# M411_unitA register map
File version: 2.0.2.2
Registers are 32-bit, read-write, reset 0x0 unless marked. A register's access mark holds for its fields unless they carry their own. Offsets are from the block's base; [hi:lo] are bit positions; {n}, {i} and the like mark numbered series.

## PF — Port F (PF)
Base 0x400C0500
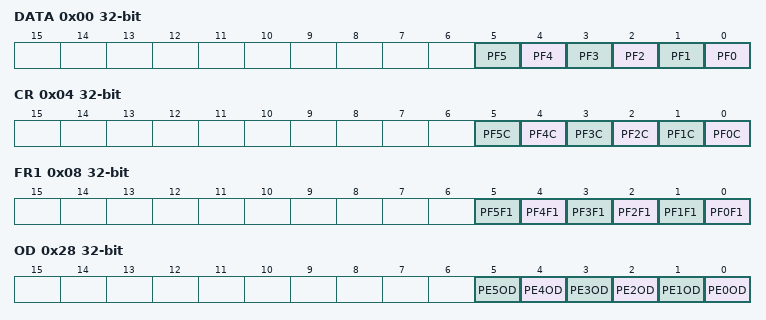
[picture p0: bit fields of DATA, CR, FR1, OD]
0x00 DATA — Port F Data Register
  [n] PF{n} (n=0..5)
0x04 CR — Port F Output Control Register
  [n] PF{n}C (n=0..5)
0x08 FR1 — Port F Function Register 1
  [n] PF{n}F1 (n=0..5)
0x28 OD — Port F Open-drain Control Register
  [n] PE{n}OD (n=0..5)
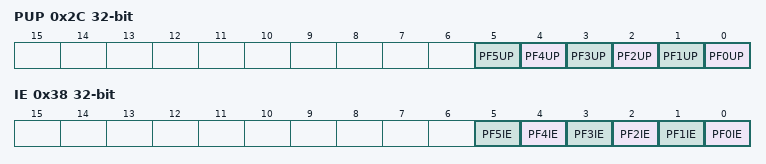
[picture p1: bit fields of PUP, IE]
0x2C PUP — Port F Pull-up Control Register
  [n] PF{n}UP (n=0..5)
0x38 IE — Port F Input Control Register
  [n] PF{n}IE (n=0..5)

## PG — Port G (PG)
Base 0x400C0600
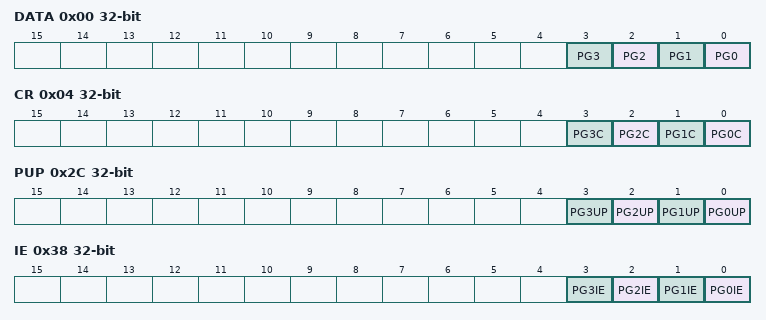
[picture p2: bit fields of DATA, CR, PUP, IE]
0x00 DATA — Port G Data Register
  [n] PG{n} (n=0..3)
0x04 CR — Port G Output Control Register
  [n] PG{n}C (n=0..3)
0x2C PUP — Port G Pull-up Control Register
  [n] PG{n}UP (n=0..3)
0x38 IE — Port G Input Control Register
  [n] PG{n}IE (n=0..3)

## TB0 — 16-bit Timer_Event Counter (TB)
Base 0x400C4000
Same registers: TB1 0x400C4100, TB2 0x400C4200
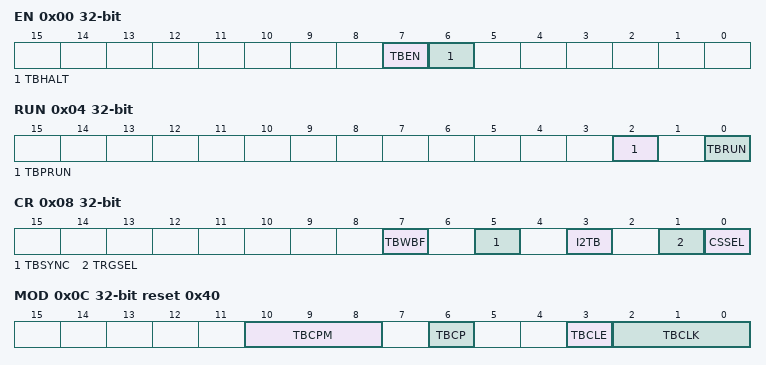
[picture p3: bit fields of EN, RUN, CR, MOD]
0x00 EN — TB Enable Register
  [7] TBEN, [6] TBHALT
0x04 RUN — TB RUN Register
  [2] TBPRUN, [0] TBRUN
0x08 CR — TB Control Register
  [7] TBWBF, [5] TBSYNC, [3] I2TB, [1] TRGSEL, [0] CSSEL
0x0C MOD reset 0x40 — TB Mode Register
  [10:8] TBCPM, [6] TBCP wo, [3] TBCLE, [2:0] TBCLK
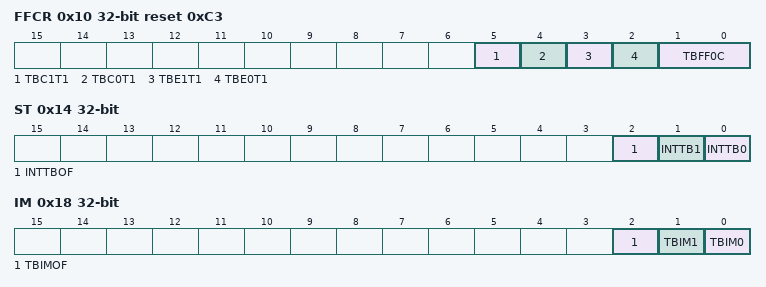
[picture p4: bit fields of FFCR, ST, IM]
0x10 FFCR reset 0xC3 — TB Flip-Flop Control Register
  [5] TBC1T1, [4] TBC0T1, [3] TBE1T1, [2] TBE0T1, [1:0] TBFF0C
0x14 ST ro — TB Status Register
  [2] INTTBOF, [1] INTTB1, [0] INTTB0
0x18 IM — TB Interrupt Mask Register
  [2] TBIMOF, [1] TBIM1, [0] TBIM0
0x1C UC ro — TB Up-counter Capture Register
  [15:0] TBUC
0x20 RG0 — TB RG0 Timer Register
  [15:0] TBRG0
0x24 RG1 — TB RG1 Timer Register
  [15:0] TBRG1
0x28 CP0 ro (reset mask 0xFFFF0000) — TB CP0 Capture Register
  [15:0] TBCP0
0x2C CP1 ro (reset mask 0xFFFF0000) — TB CP1 Capture Register
  [15:0] TBCP1

## RTC — Real Time Clock (RTC)
Base 0x400CC000
0x00 SECR 8-bit (reset mask 0x80) — RTC Second Column Register
  [6:0] SE
0x01 MINR 8-bit (reset mask 0x80) — RTC Minute Column Register
  [6:0] MI
0x02 HOURR 8-bit (reset mask 0xC0) — RTC Hour Column Register
  [5:0] HO
0x04 DAYR 8-bit (reset mask 0xF8) — RTC Day of the Week Column Register
  [2:0] WE
0x05 DATER 8-bit (reset mask 0xC0) — RTC Day Column Register
  [5:0] DA
0x06 MONTHR 8-bit (reset mask 0xE0) — RTC Month Column Register
  [4:0] MO
0x07 YEARR 8-bit reset not defined — RTC Year Column Register
  [7:0] YE
0x08 TPROD 8-bit (reset mask 0xFE) — RTC (AM_PM) Selection Register
  [0] MO0
0x09 LEAPR 8-bit (reset mask 0xFC) — RTC Leap Year Register
  [1:0] LEAP
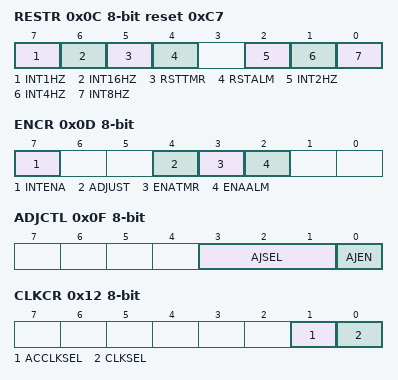
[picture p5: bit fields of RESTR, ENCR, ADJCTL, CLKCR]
0x0C RESTR 8-bit reset 0xC7 — RTC Reset Register
  [7] INT1HZ, [6] INT16HZ, [5] RSTTMR, [4] RSTALM, [2] INT2HZ, [1] INT4HZ, [0] INT8HZ
0x0D ENCR 8-bit (reset mask 0xF7)
  [7] INTENA, [4] ADJUST, [3] ENATMR, [2] ENAALM
0x0E PROTECT 8-bit reset 0xC1 — RTC protect register
  [7:0] RTCPROTECT
0x0F ADJCTL 8-bit (reset mask 0xF0) — Clock Correction Function Control Register
  [3:1] AJSEL, [0] AJEN
0x10 ADJDAT 16-bit (reset mask 0xFE00) — Clock Correction Value Register
  [8:0] ADJDAT
0x12 CLKCR 8-bit — Clock Control Register
  [1] ACCLKSEL, [0] CLKSEL
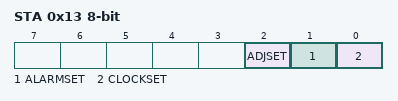
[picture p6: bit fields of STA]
0x13 STA 8-bit — Transfer Enable Register
  [2] ADJSET, [1] ALARMSET, [0] CLOCKSET
0x20 ASECR 8-bit (reset mask 0x80) — Alarm Second Column Register
  [6:0] SE
0x21 AMINR 8-bit (reset mask 0x80) — Alarm Minute Column Register
  [6:0] MI
0x22 AHOURR 8-bit (reset mask 0xC0) — Alarm Hour Column Register
  [5:0] HO
0x24 ADAYR 8-bit (reset mask 0xF8) — Alarm Day of the Week Column Register
  [2:0] WE
0x25 ADATER 8-bit (reset mask 0xC0) — Alarm Day Column Register
  [5:0] DA

## SC0 — SIO_UART (SC)
Base 0x400E1000
Same registers: SC1 0x400E1100
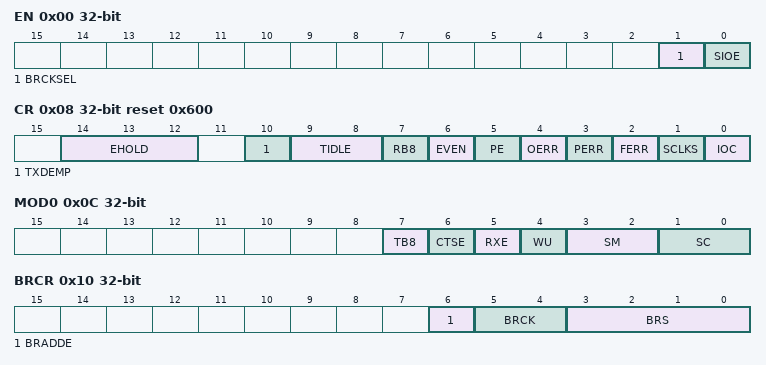
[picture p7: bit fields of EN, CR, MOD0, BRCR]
0x00 EN — SC Enable Register
  [1] BRCKSEL, [0] SIOE
0x04 BUF — SC Buffer Register
  [7:0] TB_RB
0x08 CR reset 0x600 — SC Control Register
  [14:12] EHOLD, [10] TXDEMP, [9:8] TIDLE, [7] RB8 ro, [6] EVEN, [5] PE, [4] OERR ro, [3] PERR ro, [2] FERR ro, [1] SCLKS, [0] IOC
0x0C MOD0 — SC Mode Control Register 0
  [7] TB8, [6] CTSE, [5] RXE, [4] WU, [3:2] SM, [1:0] SC
0x10 BRCR — SC Baud Rate Generator Control Register
  [6] BRADDE, [5:4] BRCK, [3:0] BRS
0x14 BRADD — SC Baud Rate Generator Control Register 2
  [3:0] BRK
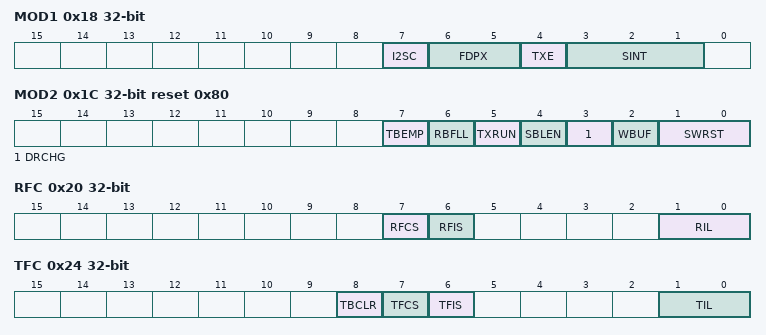
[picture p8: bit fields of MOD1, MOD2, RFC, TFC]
0x18 MOD1 — SC Mode Control Register 1
  [7] I2SC, [6:5] FDPX, [4] TXE, [3:1] SINT
0x1C MOD2 reset 0x80 — SC Mode Control Register 2
  [7] TBEMP ro, [6] RBFLL ro, [5] TXRUN ro, [4] SBLEN, [3] DRCHG, [2] WBUF, [1:0] SWRST
0x20 RFC — SC RX FIFO Configuration Register
  [7] RFCS wo, [6] RFIS, [1:0] RIL
0x24 TFC — SC TX FIFO Configuration Register
  [8] TBCLR wo, [7] TFCS wo, [6] TFIS, [1:0] TIL
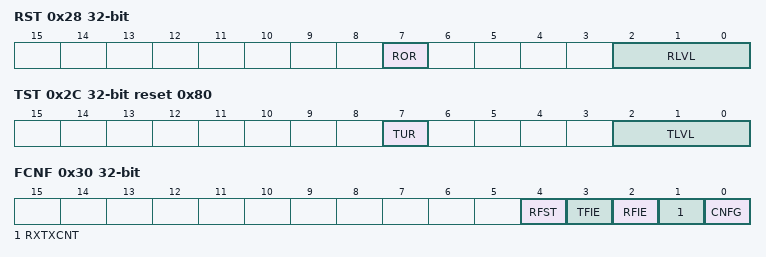
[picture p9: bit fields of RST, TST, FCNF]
0x28 RST ro — SC RX FIFO Status Register
  [7] ROR, [2:0] RLVL
0x2C TST ro reset 0x80 — SC TX FIFO Status Register
  [7] TUR, [2:0] TLVL
0x30 FCNF — SC FIFO Configuration Register
  [4] RFST, [3] TFIE, [2] RFIE, [1] RXTXCNT, [0] CNFG

## WD — Watchdog Timer (WD)
Base 0x400F2000
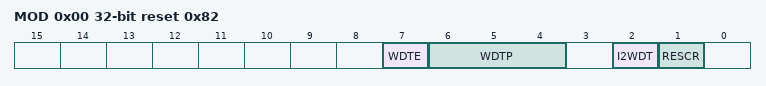
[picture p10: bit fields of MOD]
0x00 MOD reset 0x82 — Mode Register
  [7] WDTE, [6:4] WDTP, [2] I2WDT, [1] RESCR
0x04 CR wo — Control Register
  [7:0] WDCR
0x08 FLG ro — Flag Register
  [0] FLG

## CG — Clock Control (CG)
Base 0x400F3000
0x00 PROTECT reset 0xC1
  [7:0] CGPROTECT
0x04 OSCSEL — High-speed oscillation select Register
  [1:0] OSCSEL
0x08 OSCSTF ro — High-speed oscillation status Register
  [1:0] OSCF
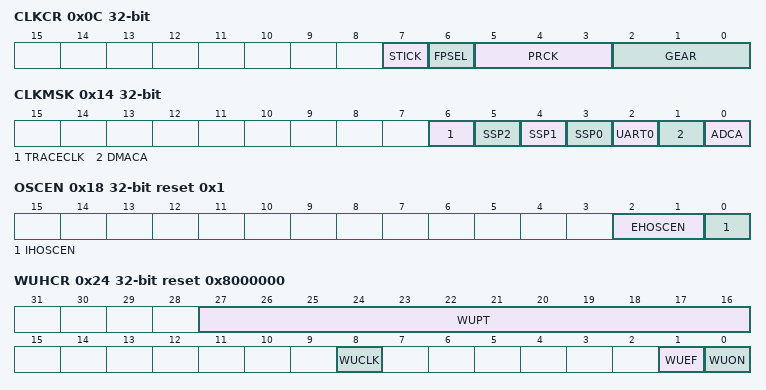
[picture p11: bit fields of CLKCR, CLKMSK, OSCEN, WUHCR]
0x0C CLKCR — Clock Control Register
  [7] STICK, [6] FPSEL, [5:3] PRCK, [2:0] GEAR
0x10 STBYCR — Standby Control Register
  [1:0] STBY
0x14 CLKMSK — Clock supply control Register
  [6] TRACECLK, [5] SSP2, [4] SSP1, [3] SSP0, [2] UART0, [1] DMACA, [0] ADCA
0x18 OSCEN reset 0x1 — Oscillation enable Register
  [2:1] EHOSCEN, [0] IHOSCEN
0x1C PLLSET — PLL setting Register
  [15:0] PLLSET
0x20 PLLEN — PLL enable Register
  [0] PLLON
0x24 WUHCR reset 0x8000000 — High-speed oscillation warm-up Control Register
  [27:16] WUPT, [8] WUCLK, [1] WUEF ro, [0] WUON wo
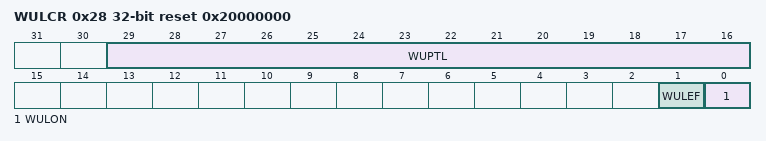
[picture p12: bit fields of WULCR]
0x28 WULCR reset 0x20000000 — Low-speed oscillation warm-up Control Register
  [29:16] WUPTL, [1] WULEF ro, [0] WULON wo
0x2C SCOCR reset 0x7 — SCOUT Control Register
  [2:0] SCOSEL

## FC — Flash Control (FC)
Base 0x5DFF0000
0x10 SECBIT reset 0x1 — Security Bit Register
  [0] SECBIT
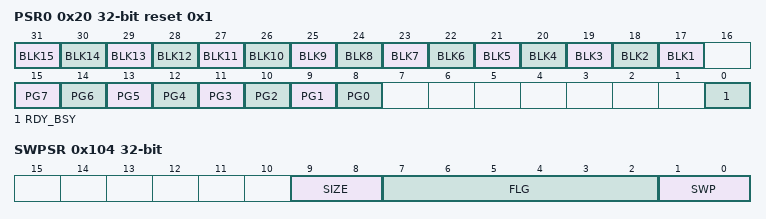
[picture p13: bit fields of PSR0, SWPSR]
0x20 PSR0 ro reset 0x1 (reset mask 0xFF) — Protect Status Register 0
  [n+16] BLK{n} (n=1..15), [n+8] PG{n} (n=0..7), [0] RDY_BSY
0x100 SR ro — Status Register
  [24] WEABORT
0x104 SWPSR ro (reset mask 0xFFFFFC00) — Swap Status Register
  [9:8] SIZE, [7:2] FLG, [1:0] SWP
0x140 AREASEL — Area Selection Register
  [2:0] AREA0
0x148 CR — Control Register
  [2:0] WEABORT
0x14C STSCLR — Status Clear Register
  [2:0] WEABORT
0x150 WCLKCR — WCLK Configuration Register
  [4:0] DIV
0x154 PROGCR — Program Counter Configuration Register
  [1:0] CNT
0x158 ERASECR reset 0x6 — Erase Counter Configuration Register
  [3:0] CNT
